# DEMOCHIP register map
File version: 1.0
Synthetic test device
CPU: CM0PLUS
Registers are 32-bit, read-write, no defined reset value unless marked. A register's access mark holds for its fields unless they carry their own. Offsets are from the block's base; lines under a group give offsets from that group; [hi:lo] are bit positions; {n}, {i} and the like mark numbered series; 'fields as' and 'values as' point back to an identical list; <NAME> marks a mode.

## Memory map
0x40000400 TIM3 — General purpose timer
0x40004400 USART2
0x40010800 GPIOA — General purpose I/O
0x40012400 ADC1 — Analog to digital converter
0x40013000 SPI1 — Serial peripheral interface
0x40013800 USART1 — Universal synchronous asynchronous receiver transmitter

## USART1 — Universal synchronous asynchronous receiver transmitter
Base 0x40013800
Same registers: USART2 0x40004400
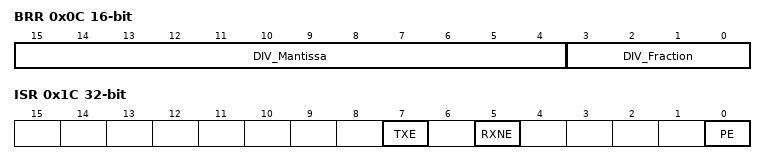
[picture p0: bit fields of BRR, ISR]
0x0C BRR 16-bit — Baud rate register
  [15:4] DIV_Mantissa, [3:0] DIV_Fraction
0x1C ISR ro — Interrupt & status register
  [7] TXE — Transmit data register empty
  [5] RXNE — Read data register not empty
  [0] PE — Parity error
0x24 RDR ro read-modifies — Receive data register
  [8:0] RDR — Receive data value
0x28 TDR wo — Transmit data register

## GPIOA — General purpose I/O
Base 0x40010800
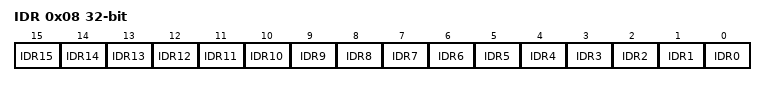
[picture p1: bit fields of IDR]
0x08 IDR ro — Input data register
  [n] IDR{n} (n=0..15) — Port input data
0x0E ODD — A register the vendor placed off its alignment

## SPI1 — Serial peripheral interface
Base 0x40013000
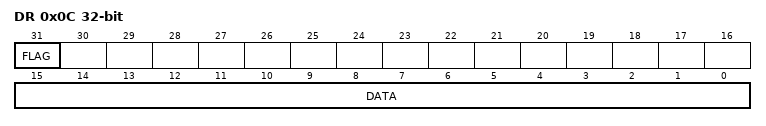
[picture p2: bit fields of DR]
0x0C DR — Data register; reading the data field pops the FIFO
  [31] FLAG — A flag next to it
  [15:0] DATA read-clears

## TIM3 — General purpose timer
Base 0x40000400
0x24 CNT 16-bit — Counter
{0x30+4i} CCR{i} (i=1..4) — Capture/compare register

## ADC1 — Analog to digital converter
Base 0x40012400
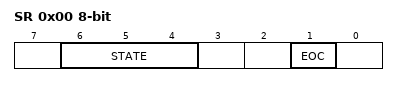
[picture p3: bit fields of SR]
0x00 SR 8-bit — Status register
  [6:4] STATE — Converter state
  [1] EOC — End of conversion
0x40 CH group — Per-channel block
  0x00 DR ro — Channel data
  0x04 CFG — Channel configuration
